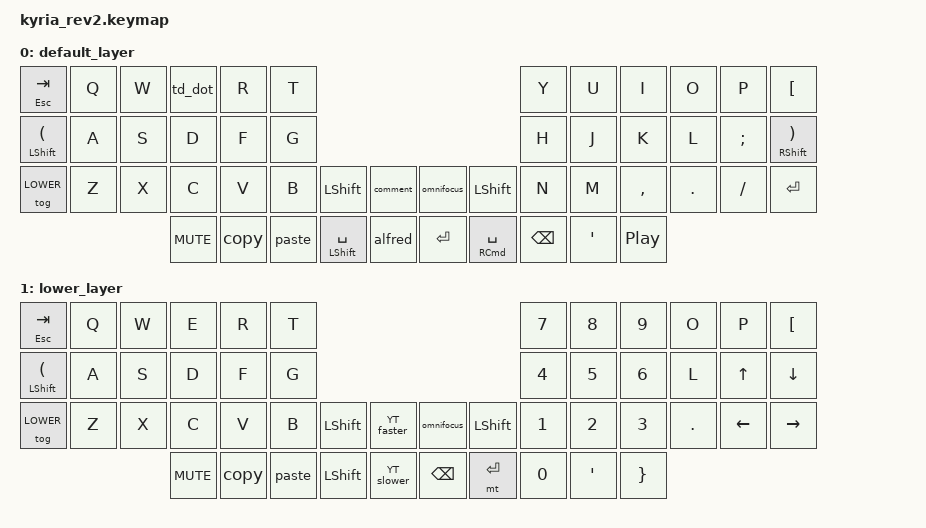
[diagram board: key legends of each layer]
/*
 * Copyright (c) 2020 The ZMK Contributors
 *
 * SPDX-License-Identifier: MIT
 */

#include <behaviors.dtsi>
#include <dt-bindings/zmk/keys.h>

#define DEFAULT 0
#define LOWER   1

&mt {
    tapping-term-ms = <100>;
};

/ {
td_dot: tap_dance_dot {
    compatible = "zmk,behavior-tap-dance";
    label = "TAP_DANCE_dot";
    #binding-cells = <0>;
    tapping-term-ms = <200>;
    bindings = <&kp E>, <&kp EXCLAMATION>;
};

    macros {
        alfred: alfred {
            label = "alfred";
            compatible = "zmk,behavior-macro";
            #binding-cells = <0>;
            bindings
                = <&macro_press &kp LCMD>
                , <&macro_tap &kp SPACE>
                , <&macro_release &kp LCMD>
                ;
        };
        copy: copy {
            label = "copy";
            compatible = "zmk,behavior-macro";
            #binding-cells = <0>;
            bindings
                = <&macro_press &kp LCMD>
                , <&macro_tap &kp I>
                , <&macro_release &kp LCMD>
                ;
        };
        paste: paste {
            label = "paste";
            compatible = "zmk,behavior-macro";
            #binding-cells = <0>;
            wait-ms = <30>;
            tap-ms = <40>;
            bindings
                = <&macro_press &kp LCMD>
                , <&macro_tap &kp DOT>
                , <&macro_release &kp LCMD>
                ;
        };
        YT_faster: YT_faster {
            label = "YT_faster";
            compatible = "zmk,behavior-macro";
            #binding-cells = <0>;
            bindings
                = <&macro_press &kp RSHIFT>
                , <&macro_tap &kp E>
                , <&macro_release &kp RSHIFT>
                ;
        };
        YT_slower: YT_slower {
            label = "YT_slower";
            compatible = "zmk,behavior-macro";
            #binding-cells = <0>;
            bindings
                = <&macro_press &kp RSHIFT>
                , <&macro_tap &kp W>
                , <&macro_release &kp RSHIFT>
                ;
        };
        omnifocus: omnifocus {
            label = "omnifocus";
            compatible = "zmk,behavior-macro";
            #binding-cells = <0>;
            bindings
                = <&macro_press &kp LCMD>
                , <&macro_press &kp LALT>
                , <&macro_tap &kp SPACE>
                , <&macro_release &kp LCMD>
                , <&macro_release &kp LALT>
                ;
        };
        comment: comment {
            label = "comment";
            compatible = "zmk,behavior-macro";
            #binding-cells = <0>;
            bindings
                = <&macro_press &kp LCMD>
                , <&macro_press &kp LALT>
                , <&macro_tap &kp A>
                , <&macro_release &kp LCMD>
                , <&macro_release &kp LALT>
                ;
        };
    };
};

/ {
	keymap {
		compatible = "zmk,keymap";

		default_layer {
// ---------------------------------------------------------------------------------------------------------------------------------
// |  ESC    |  '  |  ,  |  .   |  P   |  Y    |                                               |  F   |  G   |  C   |  R  |  L  |   /  ?   |
// | SHIFT ( |  A  |  O  |  E   |  U   |  I    |                                               |  D   |  H   |  T   |  N  |  S  |  ) SHIFT |
// | LOWER   |  ;  |  Q  |  J   |  K   |  X    |  SHIFT | COMMENT  ||     || OMNIFOCUS | NASA  |  B   |  M   |  W   |  V  |  Z  |   RETURN |
//                       | KNOB | COPY | PASTE |  ---   | ALFRED   ||     || ENTER     |  ---  | BKSP |  -   | PLAY |
			bindings = <
	&mt ESC TAB     &kp Q &kp W &td_dot    &kp R   &kp T                                                             &kp Y    &kp U   &kp I     &kp O   &kp P    &kp LEFT_BRACKET
	&mt LSHIFT LPAR     &kp A &kp S &kp D      &kp F   &kp G                                                             &kp H    &kp J   &kp K     &kp L   &kp SEMI &mt RSHIFT RPAR
	&tog LOWER  &kp Z &kp X &kp C      &kp V   &kp B  &kp LSHFT      &comment  &omnifocus &kp LSHFT      &kp N    &kp M   &kp COMMA &kp DOT &kp FSLH &kp RETURN
	                            &kp K_MUTE &copy   &paste &mt LSHFT SPACE &alfred   &kp RET    &mt RCMD SPACE &kp BSPC &kp SQT &kp C_PLAY_PAUSE
			>;

			sensor-bindings = <&inc_dec_kp C_VOL_DN C_VOL_UP>;
		};

    lower_layer {
// ---------------------------------------------------------------------------------------------------------------------------------
// |  ESC    |  '  |  ,  |  .   |  P    |  Y    |                                               |  7   |  8   |  9   |  R  |  L  | / |
// | SHIFT ( |  A  |  O  |  E   |  U    |  I    |                                               |  4   |  5   |  6   |  N  |  ⬆  | ↓ |
// | LOWER   |  ;  |  Q  |  J   |  K    |  X    |  SHIFT | FASTER   ||     || OMNIFOCUS | ENTER |  1   |  2   |  3   |  V  |  ←  | → |
//                       | KNOB |  COPY | PASTE |  ---   | SLOWER   ||     || BKSP      |  ---  |  0   |  -   |  +   |
			bindings = <
	&mt ESC TAB     &kp Q &kp W &kp E      &kp R           &kp T                                                           &kp N7   &kp N8   &kp N9   &kp O   &kp P    &kp LEFT_BRACKET
	&mt LSHIFT LPAR &kp A &kp S &kp D      &kp F           &kp G                                                           &kp N4   &kp N5   &kp N6   &kp L   &kp UP   &kp DOWN
	&tog LOWER      &kp Z &kp X &kp C      &kp V           &kp B           &kp LSHFT &YT_faster       &omnifocus &kp LSHFT &kp N1   &kp N2   &kp N3   &kp DOT &kp LEFT &kp RIGHT
	                            &kp K_MUTE &copy &paste &kp LSHFT &YT_slower  &kp BSPC   &mt RET   &kp N0   &kp SQT  &kp RBRC
			>;

			sensor-bindings = <&inc_dec_kp PG_UP PG_DN>;
		};
	};
};
